# STM32G071 register map
File version: 2.5
CPU: CM0 r0p1, little endian, MPU, no FPU, 2 interrupt priority bits
Registers are 32-bit, read-write, reset 0x0 unless marked. A register's access mark holds for its fields unless they carry their own. Offsets are from the block's base; [hi:lo] are bit positions; {n}, {i} and the like mark numbered series.

## LPUART — Universal synchronous asynchronous receiver transmitter
Base 0x40008000
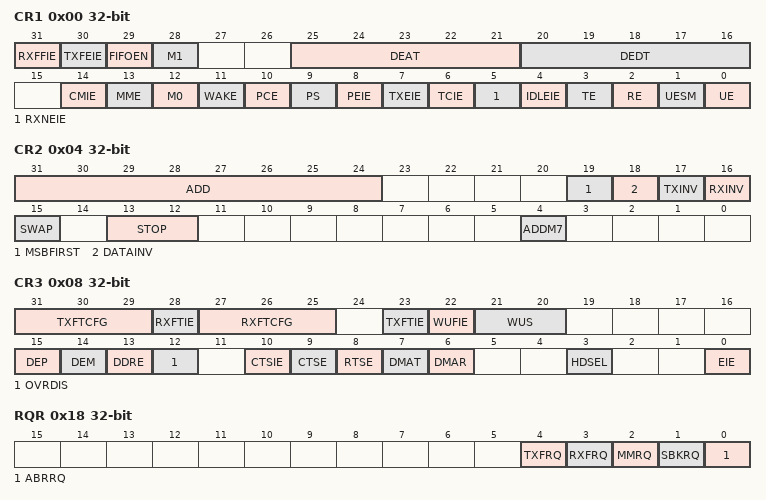
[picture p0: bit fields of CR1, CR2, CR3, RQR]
0x00 CR1 — Control register 1
  [31] RXFFIE — RXFIFO Full interrupt enable
    0=Disabled (Interrupt inhibited); 1=Enabled (USART interrupt generated when RXFF = 1 in the USART_ISR register)
  [30] TXFEIE — TXFIFO empty interrupt enable
    0=Disabled (Interrupt inhibited); 1=Enabled (USART interrupt generated when TXFE = 1 in the USART_ISR register)
  [29] FIFOEN — FIFO mode enable
    0=Disabled (FIFO mode is disabled); 1=Enabled (FIFO mode is enabled)
  [28] M1 — Word length
    0=M0 (Use M0 to set the data bits); 1=Bit7 (1 start bit, 7 data bits, n stop bits)
  [25:21] DEAT — DEAT0
  [20:16] DEDT — DEDT0
  [14] CMIE — Character match interrupt enable
    0=Disabled (Interrupt is disabled); 1=Enabled (Interrupt is generated when the CMF bit is set in the ISR register)
  [13] MME — Mute mode enable
    0=Disabled (Receiver in active mode permanently); 1=Enabled (Receiver can switch between mute mode and active mode)
  [12] M0 — Word length
    0=Bit8 (1 start bit, 8 data bits, n stop bits); 1=Bit9 (1 start bit, 9 data bits, n stop bits)
  [11] WAKE — Receiver wakeup method
    0=Idle line; 1=Address mask
  [10] PCE — Parity control enable
    0=Disabled (Parity control disabled); 1=Enabled (Parity control enabled)
  [9] PS — Parity selection
    0=Even parity; 1=Odd (Odd parity)
  [8] PEIE — PE interrupt enable
    0=Disabled (Interrupt is disabled); 1=Enabled (Interrupt is generated whenever PE=1 in the ISR register)
  [7] TXEIE — interrupt enable
    0=Disabled (Interrupt is disabled); 1=Enabled (Interrupt is generated whenever TXE=1 in the ISR register)
  [6] TCIE — Transmission complete interrupt enable
    0=Disabled (Interrupt is disabled); 1=Enabled (Interrupt is generated whenever TC=1 in the ISR register)
  [5] RXNEIE — RXNE interrupt enable
    0=Disabled (Interrupt is disabled); 1=Enabled (Interrupt is generated whenever ORE=1 or RXNE=1 in the ISR register)
  [4] IDLEIE — IDLE interrupt enable
    0=Disabled (Interrupt is disabled); 1=Enabled (Interrupt is generated whenever IDLE=1 in the ISR register)
  [3] TE — Transmitter enable
    0=Disabled (Transmitter is disabled); 1=Enabled (Transmitter is enabled)
  [2] RE — Receiver enable
    0=Disabled (Receiver is disabled); 1=Enabled (Receiver is enabled)
  [1] UESM — USART enable in Stop mode
    0=Disabled (USART not able to wake up the MCU from Stop mode); 1=Enabled (USART able to wake up the MCU from Stop mode)
  [0] UE — USART enable
    0=Disabled (UART is disabled); 1=Enabled (UART is enabled)
0x04 CR2 — Control register 2
  [31:24] ADD — Address of the USART node
  [19] MSBFIRST — Most significant bit first
    0=LSB (data is transmitted/received with data bit 0 first, following the start bit); 1=MSB (data is transmitted/received with MSB (bit 7/8/9) first, following the start bit)
  [18] DATAINV — Binary data inversion
    0=Positive (Logical data from the data register are send/received in positive/direct logic); 1=Negative (Logical data from the data register are send/received in negative/inverse logic)
  [17] TXINV — TX pin active level inversion
    0=Standard (TX pin signal works using the standard logic levels); 1=Inverted (TX pin signal values are inverted)
  [16] RXINV — RX pin active level inversion
    0=Standard (RX pin signal works using the standard logic levels); 1=Inverted (RX pin signal values are inverted)
  [15] SWAP — Swap TX/RX pins
    0=Standard (TX/RX pins are used as defined in standard pinout); 1=Swapped (The TX and RX pins functions are swapped)
  [13:12] STOP — STOP bits
    0=1 stop bit; 2=2 stop bit
  [4] ADDM7 — 7-bit Address Detection/4-bit Address Detection
    0=Bit4 (4-bit address detection); 1=Bit7 (7-bit address detection)
0x08 CR3 — Control register 3
  [31:29] TXFTCFG — TXFIFO threshold configuration
    0=Depth_1_8 (TXFIFO reaches 1/8 of its depth); 1=Depth_1_4 (TXFIFO reaches 1/4 of its depth); 2=Depth_1_2 (TXFIFO reaches 1/2 of its depth); 3=Depth_3_4 (TXFIFO reaches 3/4 of its depth); 4=Depth_7_8 (TXFIFO reaches 7/8 of its depth); 5=Empty (TXFIFO becomes empty)
  [28] RXFTIE — RXFIFO threshold interrupt enable
    0=Disabled (Interrupt inhibited); 1=Enabled (USART interrupt generated when Receive FIFO reaches the threshold programmed in RXFTCFG)
  [27:25] RXFTCFG — Receive FIFO threshold configuration
    0=Depth_1_8 (RXFIFO reaches 1/8 of its depth); 1=Depth_1_4 (RXFIFO reaches 1/4 of its depth); 2=Depth_1_2 (RXFIFO reaches 1/2 of its depth); 3=Depth_3_4 (RXFIFO reaches 3/4 of its depth); 4=Depth_7_8 (RXFIFO reaches 7/8 of its depth); 5=Full (RXFIFO becomes full)
  [23] TXFTIE — threshold interrupt enable
    0=Disabled (Interrupt inhibited); 1=Enabled (USART interrupt generated when Transmit FIFO reaches the threshold programmed in TXFTCFG)
  [22] WUFIE — Wakeup from Stop mode interrupt enable
    0=Disabled (Interrupt is inhibited); 1=Enabled (An USART interrupt is generated whenever WUF=1 in the ISR register)
  [21:20] WUS — Wakeup from Stop mode interrupt flag selection
    0=Address (WUF active on address match); 2=Start (WuF active on Start bit detection); 3=RXNE (WUF active on RXNE)
  [15] DEP — Driver enable polarity selection
    0=High (DE signal is active high); 1=Low (DE signal is active low)
  [14] DEM — Driver enable mode
    0=Disabled (DE function is disabled); 1=Enabled (The DE signal is output on the RTS pin)
  [13] DDRE — DMA Disable on Reception Error
    0=NotDisabled (DMA is not disabled in case of reception error); 1=Disabled (DMA is disabled following a reception error)
  [12] OVRDIS — Overrun Disable
    0=Enabled (Overrun Error Flag, ORE, is set when received data is not read before receiving new data); 1=Disabled (Overrun functionality is disabled. If new data is received while the RXNE flag is still set the ORE flag is not set and the new received data overwrites the previous content of the RDR register)
  [10] CTSIE — CTS interrupt enable
    0=Disabled (Interrupt is inhibited); 1=Enabled (An interrupt is generated whenever CTSIF=1 in the ISR register)
  [9] CTSE — CTS enable
    0=Disabled (CTS hardware flow control disabled); 1=Enabled (CTS mode enabled, data is only transmitted when the CTS input is asserted)
  [8] RTSE — RTS enable
    0=Disabled (RTS hardware flow control disabled); 1=Enabled (RTS output enabled, data is only requested when there is space in the receive buffer)
  [7] DMAT — DMA enable transmitter
    0=Disabled (DMA mode is disabled for transmission); 1=Enabled (DMA mode is enabled for transmission)
  [6] DMAR — DMA enable receiver
    0=Disabled (DMA mode is disabled for reception); 1=Enabled (DMA mode is enabled for reception)
  [3] HDSEL — Half-duplex selection
    0=NotSelected (Half duplex mode is not selected); 1=Selected (Half duplex mode is selected)
  [0] EIE — Error interrupt enable
    0=Disabled (Interrupt is inhibited); 1=Enabled (An interrupt is generated when FE=1 or ORE=1 or NF=1 in the ISR register)
0x0C BRR — Baud rate register
  [19:0] BRR
0x18 RQR wo — Request register
  [4] TXFRQ — Transmit data flush request
    1=Discard (Set the TXE flags. This allows to discard the transmit data)
  [3] RXFRQ — Receive data flush request
    1=Discard (clears the RXNE flag. This allows to discard the received data without reading it, and avoid an overrun condition)
  [2] MMRQ — Mute mode request
    1=Mute (Puts the USART in mute mode and sets the RWU flag)
  [1] SBKRQ — Send break request
    1=Break (sets the SBKF flag and request to send a BREAK on the line, as soon as the transmit machine is available)
  [0] ABRRQ — Auto baud rate request
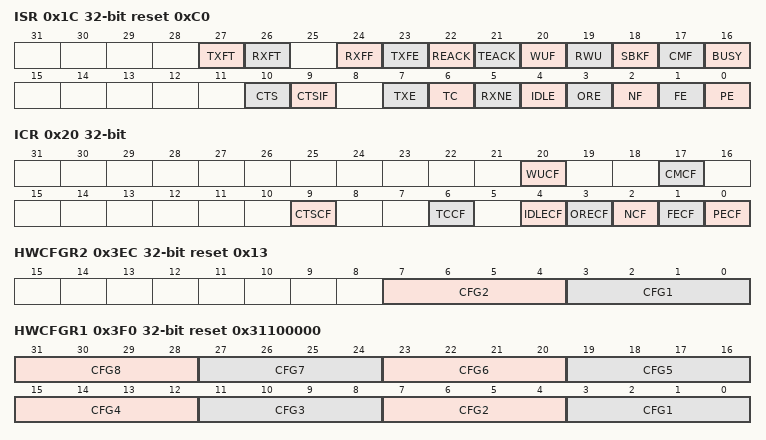
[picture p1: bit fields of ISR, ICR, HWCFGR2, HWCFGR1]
0x1C ISR ro reset 0xC0 — Interrupt & status register
  [27] TXFT — TXFIFO threshold flag
    0=NotReached (TXFIFO does not reach the programmed threshold.); 1=Reached (TXFIFO reached the programmed threshold.)
  [26] RXFT — RXFIFO threshold flag
    0=NotReached (Receive FIFO does not reach the programmed threshold.); 1=Reached (Receive FIFO reached the programmed threshold.)
  [24] RXFF — RXFIFO Full
    0=NotFull (RXFIFO not full.); 1=Full (RXFIFO Full.)
  [23] TXFE — TXFIFO Empty
    0=NotEmpty (TXFIFO not empty.); 1=Empty (TXFIFO empty.)
  [22] REACK
  [21] TEACK
  [20] WUF
  [19] RWU
    0=Active (Receiver in Active mode); 1=Mute (Receiver in Mute mode)
  [18] SBKF
    0=No break character transmitted; 1=Break character transmitted
  [17] CMF
    0=NoMatch (No Character match detected); 1=Match (Character match detected)
  [16] BUSY
    0=Idle (USART is idle (no reception)); 1=Busy (Reception on going)
  [10] CTS
    0=Set (CTS line set); 1=Reset (CTS line reset)
  [9] CTSIF
    0=NotChanged (No change occurred on the CTS status line); 1=Changed (A change occurred on the CTS status line)
  [7] TXE
    0=Full (Transmit FIFO is full); 1=NotFull (Transmit FIFO is not full)
  [6] TC
    0=TxNotComplete (Transmission is not complete); 1=TxComplete (Transmission is complete)
  [5] RXNE
    0=NoData (Data is not received); 1=DataReady (Received data is ready to be read)
  [4] IDLE
    0=No Idle Line is detected; 1=Idle Line is detected
  [3] ORE
    0=No Overrun error; 1=Overrun error is detected
  [2] NF
    0=No noise is detected; 1=Noise is detected
  [1] FE
    0=NoError (No Framing error is detected); 1=Error (Framing error or break character is detected)
  [0] PE
    0=NoError (No parity error); 1=Error (Parity error)
0x20 ICR wo — Interrupt flag clear register
  [20] WUCF write-1-clears — Wakeup from Stop mode clear flag
    1=Clears the WUF flag in the ISR register
  [17] CMCF write-1-clears — Character match clear flag
    1=Clears the CMF flag in the ISR register
  [9] CTSCF write-1-clears — CTS clear flag
    1=Clears the CTSIF flag in the ISR register
  [6] TCCF write-1-clears — Transmission complete clear flag
    1=Clears the TC flag in the ISR register
  [4] IDLECF write-1-clears — Idle line detected clear flag
    1=Clears the IDLE flag in the ISR register
  [3] ORECF write-1-clears — Overrun error clear flag
    1=Clears the ORE flag in the ISR register
  [2] NCF write-1-clears — Noise detected clear flag
    1=Clears the NF flag in the ISR register
  [1] FECF write-1-clears — Framing error clear flag
    1=Clears the FE flag in the ISR register
  [0] PECF write-1-clears — Parity error clear flag
    1=Clears the PE flag in the ISR register
0x24 RDR ro — Receive data register
  [8:0] RDR — Receive data value
0x28 TDR — Transmit data register
  [8:0] TDR — Transmit data value
0x2C PRESC — Prescaler register
  [3:0] PRESCALER — Clock prescaler
    0=Div1 (/1); 1=Div2 (/2); 2=Div4 (/4); 3=Div6 (/6); 4=Div8 (/8); 5=Div10 (/10); 6=Div12 (/12); 7=Div16 (/16); 8=Div32 (/32); 9=Div64 (/64); 10=Div128 (/128); 11=Div256 (/256)
0x3EC HWCFGR2 reset 0x13 — LPUART Hardware Configuration register 2
  [7:4] CFG2 — LUART hardware configuration 2
  [3:0] CFG1 — LUART hardware configuration 1
0x3F0 HWCFGR1 reset 0x31100000 — LPUART Hardware Configuration register 1
  [4n-1:4n-4] CFG{n} (n=4..8) — LUART hardware configuration 2
  [11:8] CFG3 — LUART hardware configuration 1
  [7:4] CFG2 — LUART hardware configuration 2
  [3:0] CFG1 — LUART hardware configuration 1
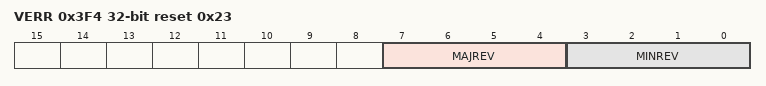
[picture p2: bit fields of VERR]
0x3F4 VERR ro reset 0x23 — EXTI IP Version register
  [7:4] MAJREV — Major Revision number
  [3:0] MINREV — Minor Revision number
0x3F8 IPIDR ro reset 0x130003 — EXTI Identification register
  [31:0] IPID — IP Identification
0x3FC SIDR ro reset 0xA3C5DD01 — EXTI Size ID register
  [31:0] SID — Size Identification
